# f2838x_cm_mpu_regs register map
Vendor: Texas Instruments
Peripheral module from a debugger description file (folder C2000).
Address unit: 16 bits
Registers are 32-bit, read-write, no defined reset value unless marked. A register's access mark holds for its fields unless they carry their own. Offsets are as the file gives them; lines under a group give offsets from that group; [hi:lo] are bit positions; {n}, {i} and the like mark numbered series; 'fields as' and 'values as' point back to an identical list; <NAME> marks a mode.

## MPU — MPU Registers
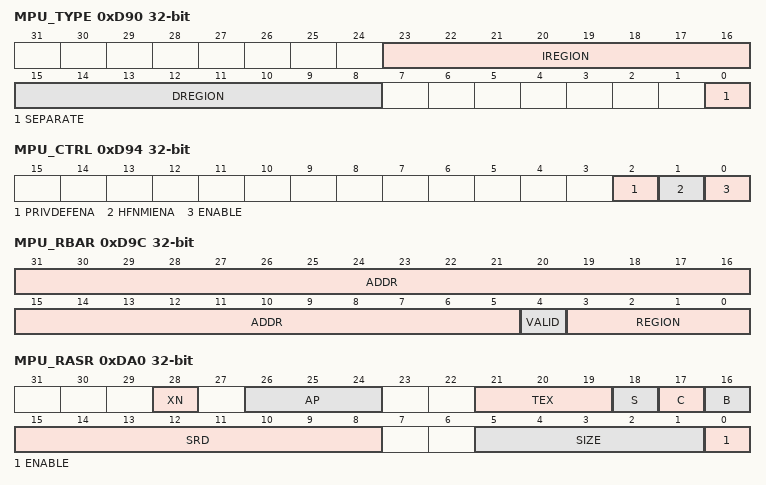
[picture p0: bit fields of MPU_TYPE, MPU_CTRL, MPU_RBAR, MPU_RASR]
0xD90 MPU_TYPE ro
  [23:16] IREGION — Indicates the number of supported MPU instruction regions
  [15:8] DREGION — Indicates the number of supported MPU data regions
  [0] SEPARATE — unified/separate instruction and date memory maps
0xD94 MPU_CTRL — MPU Control Register
  [2] PRIVDEFENA — Enables privileged software access to the default memory map
  [1] HFNMIENA — Enables MPU during hard fault, NMI, and FAULTMASK handlers.
  [0] ENABLE — Enables the MPU
0xD98 MPU_RNR — MPU Region Number Register
  [7:0] REGION — MPU region referred by the MPU_RBAR and MPU_RASR registers.
0xD9C MPU_RBAR — MPU Region Base Address Register
  [31:5] ADDR — Region base address field
  [4] VALID — MPU Region Number valid bit
  [3:0] REGION — MPU region field
0xDA0 MPU_RASR — MPU Region Attribute and Size Register
  [28] XN — Instruction access disable bit
  [26:24] AP — Memory access attribute
  [21:19] TEX — Memory access attribute
  [18] S — Memory access attribute
  [17] C — Memory access attribute
  [16] B — Memory access attribute
  [15:8] SRD — Subregion disable bits
  [5:1] SIZE — Specifies the size of the MPU protection region.
  [0] ENABLE — Region enable bit.
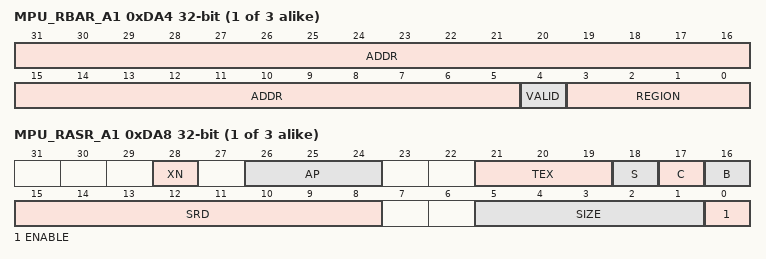
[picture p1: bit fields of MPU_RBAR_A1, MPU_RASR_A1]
{0xD9C+8i} MPU_RBAR_A{i} (i=1..3) — Alias of RBAR
  fields as MPU_RBAR
{0xDA0+8i} MPU_RASR_A{i} (i=1..3) — Alias of RASR
  fields as MPU_RASR
